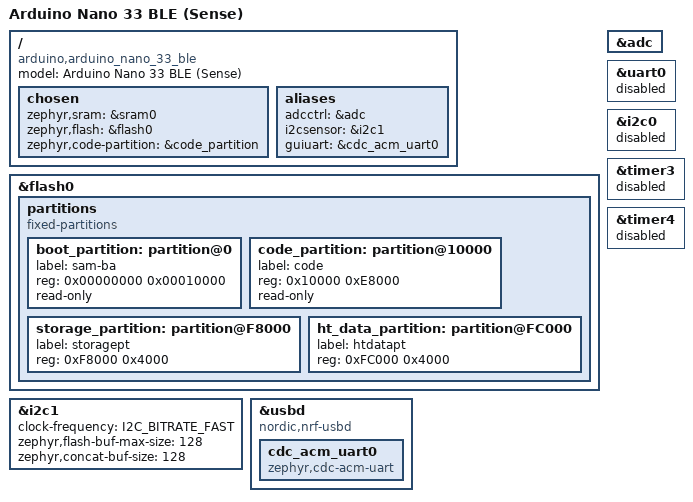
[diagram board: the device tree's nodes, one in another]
/ {
	model = "Arduino Nano 33 BLE (Sense)";
	compatible = "arduino,arduino_nano_33_ble";

	chosen {
		/delete-property/ zephyr,console;
    /delete-property/ zephyr,shell-uart;
		/delete-property/ zephyr,uart-mcumgr;
		/delete-property/ zephyr,bt-mon-uart;
		/delete-property/ zephyr,bt-c2h-uart;
		zephyr,sram = &sram0;
		zephyr,flash = &flash0;
		zephyr,code-partition = &code_partition;

		// Uncomment the below line for kernel logging to a second USB CDC port
		// Also uncomment the extra cdc at the bottom of the file
		//   zephyr,console = &cdc_acm_uart1;
	};

  aliases {
    adcctrl = &adc;
    i2csensor = &i2c1;
		guiuart = &cdc_acm_uart0;
  };
};

/* Flash Layout
 *    Bootloader    0x00000 - 0x10000  (Size 0x10000 65536 Bytes)
 *    Code          0x10000 - 0xFB000  (Size 0xEB000 962560 Bytes)
 *    BTPersistance 0xFB000 - 0xFD000  (Size 0x2000 8192 Bytes)
 *    HTData        0xFD000 - 0x100000 (Size 0x3000 12288 Bytes)
 */

/delete-node/ &storage_partition;
/delete-node/ &code_partition;

&flash0 {
	partitions {
		compatible = "fixed-partitions";
		#address-cells = <1>;
		#size-cells = <1>;

		boot_partition: partition@0 {
			label = "sam-ba";
			reg = <0x00000000 0x00010000>;
			read-only;
		};

		code_partition: partition@10000 {
			label = "code";
			reg = <0x10000 0xE8000>;
			read-only;
		};

		storage_partition: partition@F8000 {
			label = "storagept";
			reg = <0xF8000 0x4000>;
		};

    ht_data_partition: partition@FC000 {
        label = "htdatapt";
        reg = <0xFC000 0x4000>;
    };
	};
};

&adc {
	status = "okay";
};

&uart0 {
	status = "disabled";
};

&i2c0 {
	status = "disabled";
};

&i2c1 {
	status = "okay";
	clock-frequency = <I2C_BITRATE_FAST>;
	zephyr,flash-buf-max-size = <128>;
	zephyr,concat-buf-size = <128>;
};

/* Disable Timer3, used by PPM output
 */
&timer3 {
    status = "disabled";
};

/* Disable Timer4, used by PPM input
 */
&timer4 {
    status = "disabled";
};

zephyr_udc0: &usbd {
	compatible = "nordic,nrf-usbd";
	status = "okay";
  cdc_acm_uart0: cdc_acm_uart0 {
		compatible = "zephyr,cdc-acm-uart";
	};

  // Uncomment the below lines for kernel logging to a second USB CDC port
	/*
	cdc_acm_uart1: cdc_acm_uart1 {
		compatible = "zephyr,cdc-acm-uart";
	}; */
};

